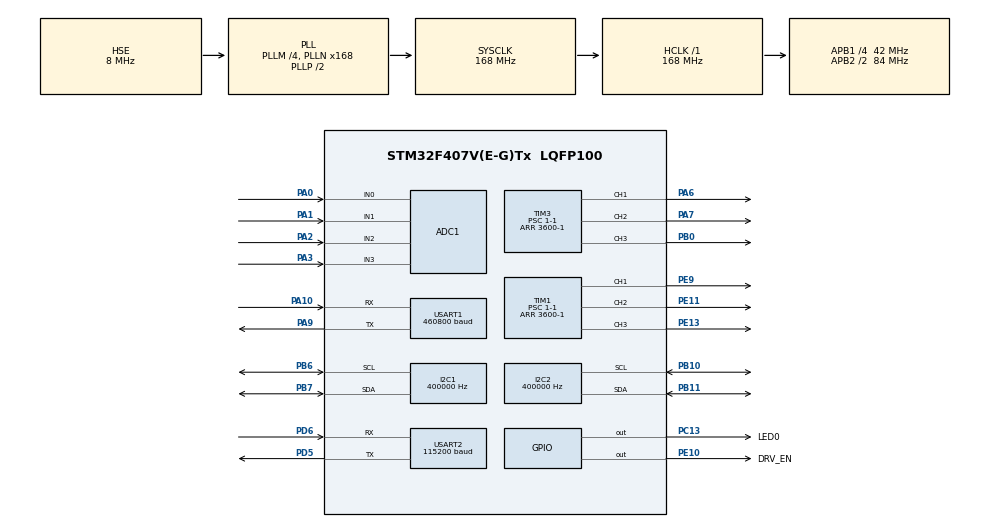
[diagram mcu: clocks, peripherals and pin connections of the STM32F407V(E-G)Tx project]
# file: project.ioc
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ADC1.Channel-0\#ChannelRegularConversion=ADC_CHANNEL_0
ADC1.Channel-1\#ChannelRegularConversion=ADC_CHANNEL_1
ADC1.Channel-2\#ChannelRegularConversion=ADC_CHANNEL_2
ADC1.Channel-3\#ChannelRegularConversion=ADC_CHANNEL_3
ADC1.InjNumberOfConversion=0
ADC1.NbrOfConversion=4
ADC1.NbrOfConversionFlag=1
ADC1.Rank-0\#ChannelRegularConversion=1
ADC1.Rank-1\#ChannelRegularConversion=2
ADC1.Rank-2\#ChannelRegularConversion=3
ADC1.Rank-3\#ChannelRegularConversion=4
ADC1.SamplingTime-0\#ChannelRegularConversion=ADC_SAMPLETIME_3CYCLES
ADC1.SamplingTime-1\#ChannelRegularConversion=ADC_SAMPLETIME_3CYCLES
ADC1.SamplingTime-2\#ChannelRegularConversion=ADC_SAMPLETIME_3CYCLES
ADC1.SamplingTime-3\#ChannelRegularConversion=ADC_SAMPLETIME_3CYCLES
ADC1.master=1
Dma.ADC1.2.Direction=DMA_PERIPH_TO_MEMORY
Dma.ADC1.2.FIFOMode=DMA_FIFOMODE_DISABLE
Dma.ADC1.2.Instance=DMA2_Stream0
Dma.ADC1.2.MemDataAlignment=DMA_MDATAALIGN_WORD
Dma.ADC1.2.MemInc=DMA_MINC_ENABLE
Dma.ADC1.2.Mode=DMA_CIRCULAR
Dma.ADC1.2.PeriphDataAlignment=DMA_PDATAALIGN_WORD
Dma.ADC1.2.PeriphInc=DMA_PINC_DISABLE
Dma.ADC1.2.Priority=DMA_PRIORITY_LOW
Dma.Request0=USART1_RX
Dma.Request1=USART1_TX
Dma.Request2=ADC1
Dma.Request3=USART2_RX
Dma.Request4=USART2_TX
Dma.USART1_RX.0.Direction=DMA_PERIPH_TO_MEMORY
Dma.USART1_RX.0.FIFOMode=DMA_FIFOMODE_DISABLE
Dma.USART1_RX.0.Instance=DMA2_Stream5
Dma.USART1_RX.0.MemDataAlignment=DMA_MDATAALIGN_BYTE
Dma.USART1_RX.0.MemInc=DMA_MINC_ENABLE
Dma.USART1_RX.0.Mode=DMA_NORMAL
Dma.USART1_RX.0.PeriphDataAlignment=DMA_PDATAALIGN_BYTE
Dma.USART1_RX.0.PeriphInc=DMA_PINC_DISABLE
Dma.USART1_RX.0.Priority=DMA_PRIORITY_LOW
Dma.USART1_TX.1.Direction=DMA_MEMORY_TO_PERIPH
Dma.USART1_TX.1.FIFOMode=DMA_FIFOMODE_DISABLE
Dma.USART1_TX.1.Instance=DMA2_Stream7
Dma.USART1_TX.1.MemDataAlignment=DMA_MDATAALIGN_BYTE
Dma.USART1_TX.1.MemInc=DMA_MINC_ENABLE
Dma.USART1_TX.1.Mode=DMA_NORMAL
Dma.USART1_TX.1.PeriphDataAlignment=DMA_PDATAALIGN_BYTE
Dma.USART1_TX.1.PeriphInc=DMA_PINC_DISABLE
Dma.USART1_TX.1.Priority=DMA_PRIORITY_LOW
Dma.USART2_RX.3.Direction=DMA_PERIPH_TO_MEMORY
Dma.USART2_RX.3.FIFOMode=DMA_FIFOMODE_DISABLE
Dma.USART2_RX.3.Instance=DMA1_Stream5
Dma.USART2_RX.3.MemDataAlignment=DMA_MDATAALIGN_BYTE
Dma.USART2_RX.3.MemInc=DMA_MINC_ENABLE
Dma.USART2_RX.3.Mode=DMA_NORMAL
Dma.USART2_RX.3.PeriphDataAlignment=DMA_PDATAALIGN_BYTE
Dma.USART2_RX.3.PeriphInc=DMA_PINC_DISABLE
Dma.USART2_RX.3.Priority=DMA_PRIORITY_LOW
Dma.USART2_TX.4.Direction=DMA_MEMORY_TO_PERIPH
Dma.USART2_TX.4.FIFOMode=DMA_FIFOMODE_DISABLE
Dma.USART2_TX.4.Instance=DMA1_Stream6
Dma.USART2_TX.4.MemDataAlignment=DMA_MDATAALIGN_BYTE
Dma.USART2_TX.4.MemInc=DMA_MINC_ENABLE
Dma.USART2_TX.4.Mode=DMA_NORMAL
Dma.USART2_TX.4.PeriphDataAlignment=DMA_PDATAALIGN_BYTE
Dma.USART2_TX.4.PeriphInc=DMA_PINC_DISABLE
Dma.USART2_TX.4.Priority=DMA_PRIORITY_LOW
I2C1.ClockSpeed=400000
I2C1.I2C_Mode=I2C_Fast
I2C2.ClockSpeed=400000
I2C2.I2C_Mode=I2C_Fast
Mcu.Family=STM32F4
Mcu.Name=STM32F407V(E-G)Tx
Mcu.Package=LQFP100
Mcu.UserConstants=High_band,460800
NVIC.DMA1_Stream5_IRQn=true\:0\:0\:false\:false\:true\:false\:true\:true
NVIC.DMA1_Stream6_IRQn=true\:0\:0\:false\:false\:true\:false\:true\:true
NVIC.DMA2_Stream0_IRQn=true\:0\:0\:false\:false\:true\:false\:true\:true
NVIC.DMA2_Stream5_IRQn=true\:0\:0\:false\:false\:true\:false\:true\:true
NVIC.DMA2_Stream7_IRQn=true\:0\:0\:false\:false\:true\:false\:true\:true
NVIC.PriorityGroup=NVIC_PRIORITYGROUP_4
NVIC.TIM1_BRK_TIM9_IRQn=true\:0\:0\:false\:false\:true\:true\:true\:true
NVIC.TIM1_UP_TIM10_IRQn=true\:2\:0\:true\:false\:true\:true\:true\:true
NVIC.TIM2_IRQn=true\:3\:0\:true\:false\:true\:true\:true\:true
NVIC.TIM5_IRQn=true\:1\:0\:true\:false\:true\:true\:true\:true
NVIC.TIM7_IRQn=true\:2\:0\:true\:false\:true\:true\:true\:true
NVIC.USART1_IRQn=true\:0\:0\:true\:false\:true\:true\:true\:true
NVIC.USART2_IRQn=true\:0\:0\:true\:false\:true\:true\:true\:true
PA0-WKUP.Signal=ADCx_IN0
PA1.Signal=ADCx_IN1
PA10.GPIO_PuPd=GPIO_PULLUP
PA10.Mode=Asynchronous
PA10.Signal=USART1_RX
PA13.Mode=Serial_Wire
PA13.Signal=SYS_JTMS-SWDIO
PA14.Mode=Serial_Wire
PA14.Signal=SYS_JTCK-SWCLK
PA2.Signal=ADCx_IN2
PA3.Signal=ADCx_IN3
PA6.Signal=S_TIM3_CH1
PA7.Signal=S_TIM3_CH2
PA9.Mode=Asynchronous
PA9.Signal=USART1_TX
PB0.Signal=S_TIM3_CH3
PB10.Mode=I2C
PB10.Signal=I2C2_SCL
PB11.Mode=I2C
PB11.Signal=I2C2_SDA
PB6.GPIO_Pu=GPIO_NOPULL
PB6.Mode=I2C
PB6.Signal=I2C1_SCL
PB7.GPIO_Pu=GPIO_NOPULL
PB7.Mode=I2C
PB7.Signal=I2C1_SDA
PC13-ANTI_TAMP.GPIO_Label=LED0
PC13-ANTI_TAMP.Signal=GPIO_Output
PC14-OSC32_IN.Mode=LSE-External-Oscillator
PC14-OSC32_IN.Signal=RCC_OSC32_IN
PC15-OSC32_OUT.Mode=LSE-External-Oscillator
PC15-OSC32_OUT.Signal=RCC_OSC32_OUT
PD5.Mode=Asynchronous
PD5.Signal=USART2_TX
PD6.GPIO_PuPd=GPIO_PULLUP
PD6.Mode=Asynchronous
PD6.Signal=USART2_RX
PE10.GPIO_Label=DRV_EN
PE10.Signal=GPIO_Output
PE11.Signal=S_TIM1_CH2
PE13.Signal=S_TIM1_CH3
PE9.Signal=S_TIM1_CH1
PH0-OSC_IN.Mode=HSE-External-Oscillator
PH0-OSC_IN.Signal=RCC_OSC_IN
PH1-OSC_OUT.Mode=HSE-External-Oscillator
PH1-OSC_OUT.Signal=RCC_OSC_OUT
ProjectManager.HeapSize=0x200
ProjectManager.StackSize=0x400
ProjectManager.TargetToolchain=MDK-ARM V5.32
RCC.48MHZClocksFreq_Value=84000000
RCC.AHBFreq_Value=168000000
RCC.APB1CLKDivider=RCC_HCLK_DIV4
RCC.APB1Freq_Value=42000000
RCC.APB1TimFreq_Value=84000000
RCC.APB2CLKDivider=RCC_HCLK_DIV2
RCC.APB2Freq_Value=84000000
RCC.APB2TimFreq_Value=168000000
RCC.CortexFreq_Value=168000000
RCC.HCLKFreq_Value=168000000
RCC.HSE_VALUE=8000000
RCC.HSI_VALUE=16000000
RCC.PLLM=4
RCC.PLLN=168
RCC.PLLSourceVirtual=RCC_PLLSOURCE_HSE
RCC.SYSCLKFreq_VALUE=168000000
RCC.SYSCLKSource=RCC_SYSCLKSOURCE_PLLCLK
RCC.VCOOutputFreq_Value=336000000
SH.ADCx_IN0.0=ADC1_IN0,IN0
SH.ADCx_IN1.0=ADC1_IN1,IN1
SH.ADCx_IN2.0=ADC1_IN2,IN2
SH.ADCx_IN3.0=ADC1_IN3,IN3
SH.S_TIM1_CH1.0=TIM1_CH1,PWM Generation1 CH1
SH.S_TIM1_CH2.0=TIM1_CH2,PWM Generation2 CH2
SH.S_TIM1_CH3.0=TIM1_CH3,PWM Generation3 CH3
SH.S_TIM3_CH1.0=TIM3_CH1,PWM Generation1 CH1
SH.S_TIM3_CH2.0=TIM3_CH2,PWM Generation2 CH2
SH.S_TIM3_CH3.0=TIM3_CH3,PWM Generation3 CH3
TIM1.Channel-PWM\ Generation1\ CH1=TIM_CHANNEL_1
TIM1.Channel-PWM\ Generation2\ CH2=TIM_CHANNEL_2
TIM1.Channel-PWM\ Generation3\ CH3=TIM_CHANNEL_3
TIM1.CounterMode=TIM_COUNTERMODE_CENTERALIGNED2
TIM1.Period=3600-1
TIM1.Prescaler=1-1
TIM1.TIM_MasterOutputTrigger=TIM_TRGO_UPDATE
TIM1.TIM_MasterSlaveMode=TIM_MASTERSLAVEMODE_ENABLE
TIM2.Period=500-1
TIM2.Prescaler=4200-1
TIM3.Channel-PWM\ Generation1\ CH1=TIM_CHANNEL_1
TIM3.Channel-PWM\ Generation2\ CH2=TIM_CHANNEL_2
TIM3.Channel-PWM\ Generation3\ CH3=TIM_CHANNEL_3
TIM3.Period=3600-1
TIM3.Prescaler=1-1
TIM5.Period=30-1
TIM5.Prescaler=8400-1
TIM7.Period=10-1
TIM7.Prescaler=8400-1
USART1.BaudRate=460800
USART1.VirtualMode=VM_ASYNC
USART2.BaudRate=115200
USART2.VirtualMode=VM_ASYNC
VP_TIM2_VS_ClockSourceINT.Mode=Internal
VP_TIM5_VS_ClockSourceINT.Mode=Internal
VP_TIM7_VS_ClockSourceINT.Mode=Enable_Timer
board=custom

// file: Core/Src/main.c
/* USER CODE BEGIN Header */
/**
  ******************************************************************************
  * @file           : main.c
  * @brief          : Main program body
  ******************************************************************************
  * @attention
  *
  * Copyright (c) 2024 STMicroelectronics.
  * All rights reserved.
  *
  * This software is licensed under terms that can be found in the LICENSE file
  * in the root directory of this software component.
  * If no LICENSE file comes with this software, it is provided AS-IS.
  *
  ******************************************************************************
  */
/* USER CODE END Header */
#include "main.h"
#include "adc.h"
#include "dma.h"
#include "i2c.h"
#include "tim.h"
#include "usart.h"
#include "gpio.h"

/* USER CODE BEGIN Includes */
#include "app.h"
/* USER CODE END Includes */

/* USER CODE BEGIN PV */
// using to test singchip hardware

/* USER CODE END PV */

void SystemClock_Config(void);

int main(void)
{

  /* MCU Configuration--------------------------------------------------------*/

  /* Reset of all peripherals, Initializes the Flash interface and the Systick. */
  HAL_Init();

  /* Configure the system clock */
  SystemClock_Config();

  /* Initialize all configured peripherals */
  MX_GPIO_Init();
  MX_DMA_Init();
  MX_USART1_UART_Init();
  MX_ADC1_Init();
  MX_TIM1_Init();
  MX_I2C1_Init();
  MX_TIM7_Init();
  MX_I2C2_Init();
  MX_TIM3_Init();
  MX_TIM5_Init();
  MX_USART2_UART_Init();
  MX_TIM2_Init();
  /* USER CODE BEGIN 2 */

	app_init();
	/* USER CODE END 2 */

  /* Infinite loop */
  while (1)
  {
		// loopFOC(&motor_1, target);
		// loopFOC(&motor_2, target);
    // sprintf((char*)send_buf, "D:%f,%f,%f,%f,%f,%f\r\n",
    //   motor_1.foc.shaft_velocity,
    //   motor_1.foc.current_sp,
    //   motor_1.foc.shaft_angle ,
    //   motor_2.foc.shaft_velocity,
    //   motor_2.foc.current_sp,
    //   motor_2.foc.shaft_angle );
    // usart_driver_Transmit(send_buf,sizeof(send_buf));
	}
  /* USER CODE END 3 */
}

void SystemClock_Config(void)
{
  RCC_OscInitTypeDef RCC_OscInitStruct = {0};
  RCC_ClkInitTypeDef RCC_ClkInitStruct = {0};

  /** Configure the main internal regulator output voltage
  */
  __HAL_RCC_PWR_CLK_ENABLE();
  __HAL_PWR_VOLTAGESCALING_CONFIG(PWR_REGULATOR_VOLTAGE_SCALE1);

  /** Initializes the RCC Oscillators according to the specified parameters
  * in the RCC_OscInitTypeDef structure.
  */
  RCC_OscInitStruct.OscillatorType = RCC_OSCILLATORTYPE_HSE;
  RCC_OscInitStruct.HSEState = RCC_HSE_ON;
  RCC_OscInitStruct.PLL.PLLState = RCC_PLL_ON;
  RCC_OscInitStruct.PLL.PLLSource = RCC_PLLSOURCE_HSE;
  RCC_OscInitStruct.PLL.PLLM = 4;
  RCC_OscInitStruct.PLL.PLLN = 168;
  RCC_OscInitStruct.PLL.PLLP = RCC_PLLP_DIV2;
  RCC_OscInitStruct.PLL.PLLQ = 4;
  if (HAL_RCC_OscConfig(&RCC_OscInitStruct) != HAL_OK)
  {
    Error_Handler();
  }

  /** Initializes the CPU, AHB and APB buses clocks
  */
  RCC_ClkInitStruct.ClockType = RCC_CLOCKTYPE_HCLK|RCC_CLOCKTYPE_SYSCLK
                              |RCC_CLOCKTYPE_PCLK1|RCC_CLOCKTYPE_PCLK2;
  RCC_ClkInitStruct.SYSCLKSource = RCC_SYSCLKSOURCE_PLLCLK;
  RCC_ClkInitStruct.AHBCLKDivider = RCC_SYSCLK_DIV1;
  RCC_ClkInitStruct.APB1CLKDivider = RCC_HCLK_DIV4;
  RCC_ClkInitStruct.APB2CLKDivider = RCC_HCLK_DIV2;

  if (HAL_RCC_ClockConfig(&RCC_ClkInitStruct, FLASH_LATENCY_5) != HAL_OK)
  {
    Error_Handler();
  }
}

void Error_Handler(void)
{
  __disable_irq();
  while (1)
  {
  }
}
